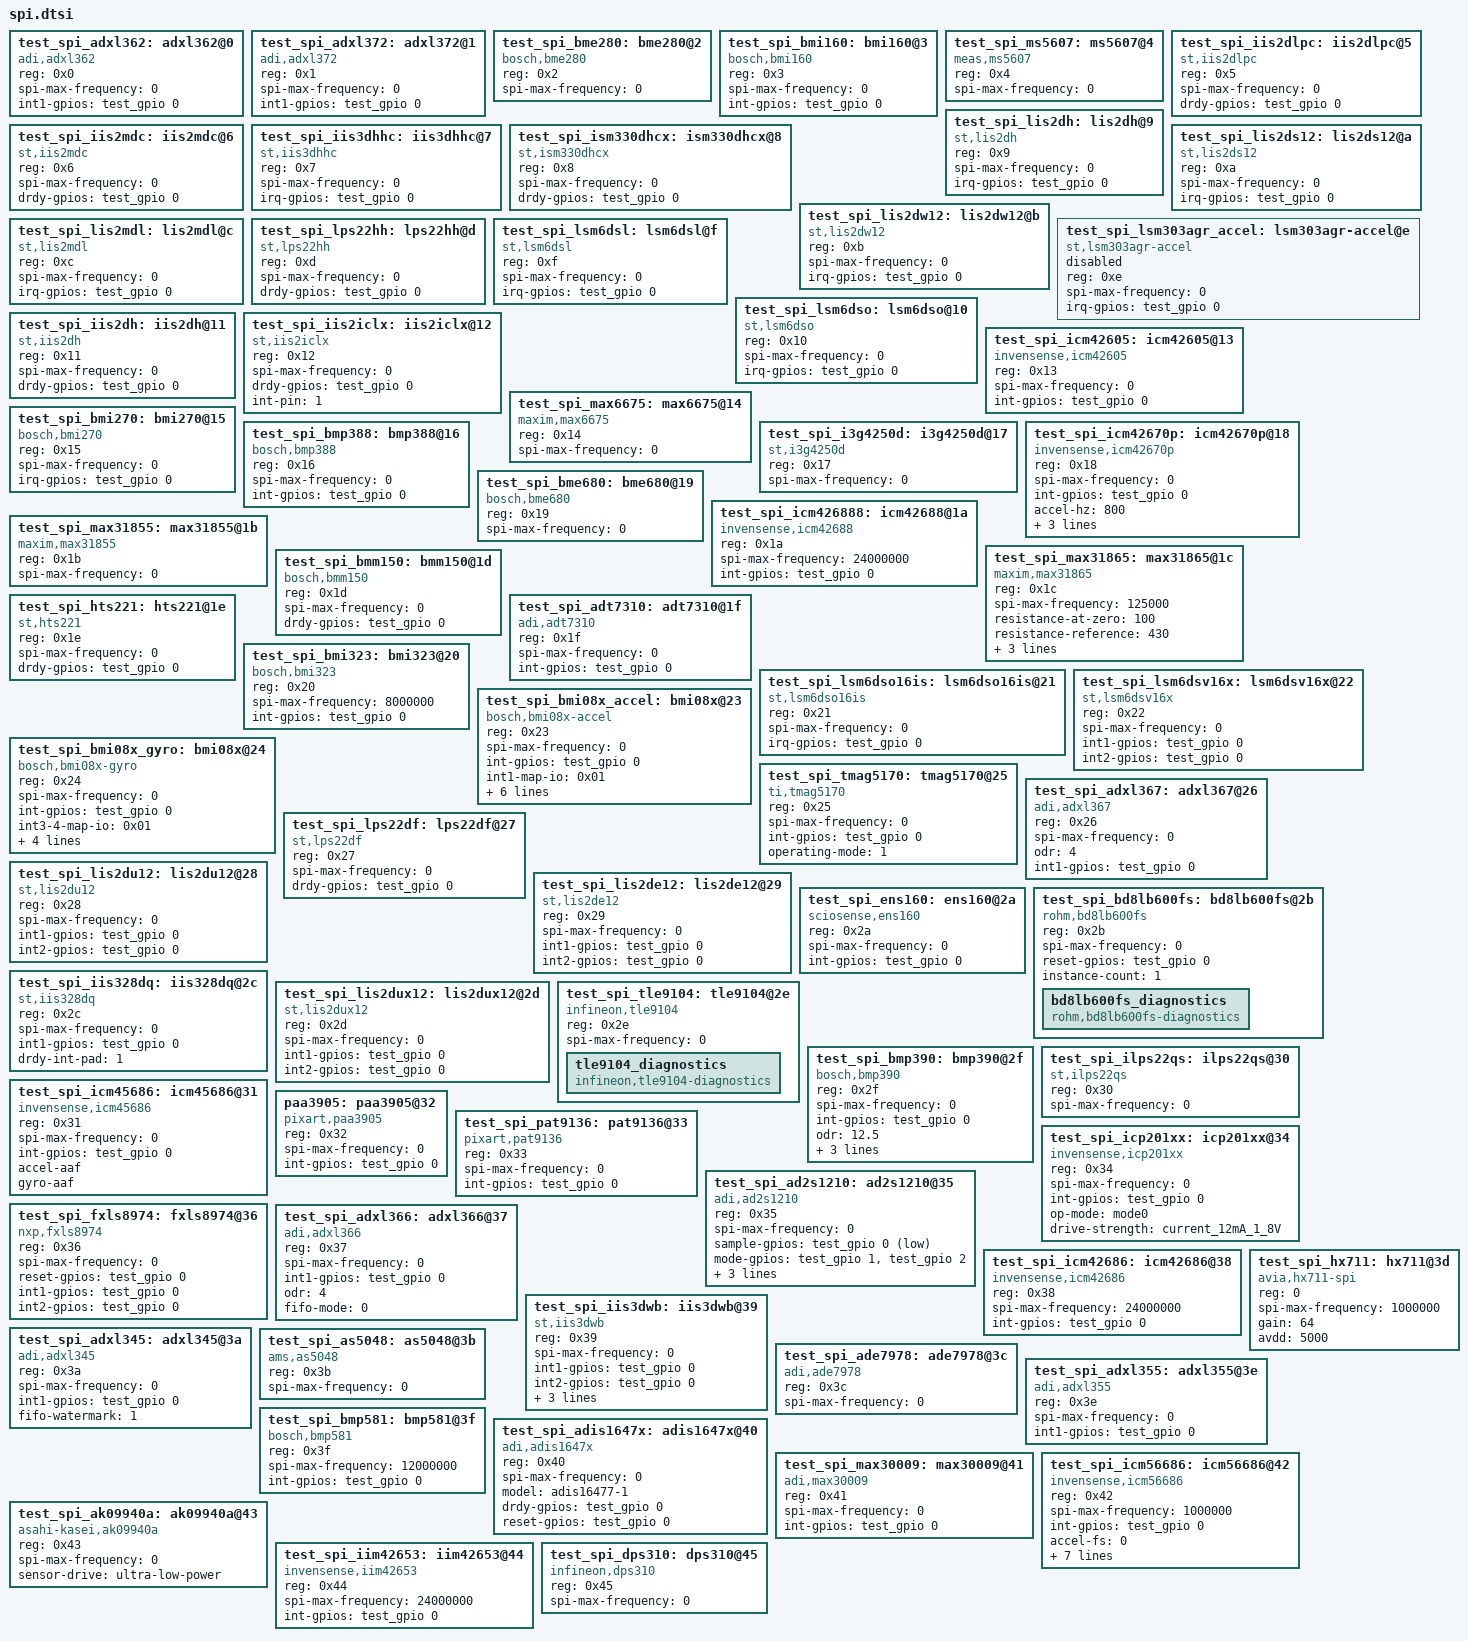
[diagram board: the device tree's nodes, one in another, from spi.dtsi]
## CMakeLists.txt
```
# SPDX-License-Identifier: Apache-2.0

cmake_minimum_required(VERSION 3.28.3)
find_package(Zephyr REQUIRED HINTS $ENV{ZEPHYR_BASE})
project(build_all)

# Exclude main when running the generic test because ztest supplies its own
target_sources_ifndef(CONFIG_GENERIC_SENSOR_TEST app PRIVATE src/main.c)
target_sources_ifdef(CONFIG_GENERIC_SENSOR_TEST app PRIVATE src/generic_test.c)
```

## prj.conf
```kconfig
# zephyr-keep-sorted-start
CONFIG_ADC=y
CONFIG_DAC=y
CONFIG_DHT20_CRC=y
CONFIG_EMUL=y
CONFIG_FUEL_GAUGE=y
CONFIG_GPIO=y
CONFIG_I2C=y
CONFIG_I3C=y
CONFIG_ICM42605_TRIGGER_NONE=y
CONFIG_ICM566XX_TRIGGER_NONE=y
CONFIG_LOG=y
CONFIG_MFD=y
CONFIG_MODBUS=y
CONFIG_MODBUS_RAW_ADU=y
CONFIG_PWM=y
CONFIG_PWM_CAPTURE=y
CONFIG_SENSOR=y
CONFIG_SENSOR_LOG_LEVEL_DBG=y
CONFIG_SERIAL=y
CONFIG_SPI=y
CONFIG_SYS_CLOCK_TICKS_PER_SEC=1000
CONFIG_TEST=y
CONFIG_TEST_USERSPACE=y
CONFIG_VCNL4040_ENABLE_ALS=y
CONFIG_W1=y
# zephyr-keep-sorted-stop
```

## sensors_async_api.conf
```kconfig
CONFIG_SENSOR_ASYNC_API=y
CONFIG_ADXL345_STREAM=y
CONFIG_ADXL362_STREAM=y
CONFIG_ADXL367_STREAM=y
CONFIG_ADXL372_STREAM=y
CONFIG_BMA4XX_STREAM=y
CONFIG_BMM350_STREAM=y
CONFIG_PAA3905_STREAM=y
CONFIG_PAT9136_STREAM=y
CONFIG_RM3100_STREAM=y
CONFIG_IIS3DWB_STREAM=y
CONFIG_LSM6DSV16X_STREAM=y
CONFIG_ICM45686_STREAM=y
CONFIG_ICM4268X_STREAM=y
CONFIG_BMI08X_GYRO_STREAM=y
CONFIG_BMI08X_ACCEL_STREAM=y
CONFIG_MAX30009_STREAM=y
CONFIG_SPA06_STREAM=y
```

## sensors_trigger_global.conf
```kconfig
# zephyr-keep-sorted-start
CONFIG_ADT7310_TRIGGER_GLOBAL_THREAD=y
CONFIG_ADT7420_TRIGGER_GLOBAL_THREAD=y
CONFIG_ADXL355_TRIGGER_GLOBAL_THREAD=y
CONFIG_ADXL362_TRIGGER_GLOBAL_THREAD=y
CONFIG_ADXL367_TRIGGER_GLOBAL_THREAD=y
CONFIG_ADXL372_TRIGGER_GLOBAL_THREAD=y
CONFIG_AMG88XX_TRIGGER_GLOBAL_THREAD=y
CONFIG_APDS9960_TRIGGER_GLOBAL_THREAD=y
CONFIG_BMA280_TRIGGER_GLOBAL_THREAD=y
CONFIG_BMG160_TRIGGER_GLOBAL_THREAD=y
CONFIG_BMI08X_ACCEL_TRIGGER_GLOBAL_THREAD=y
CONFIG_BMI08X_GYRO_TRIGGER_GLOBAL_THREAD=y
CONFIG_BMI160_TRIGGER_GLOBAL_THREAD=y
CONFIG_BMI270_TRIGGER_GLOBAL_THREAD=y
CONFIG_BMM150_TRIGGER_GLOBAL_THREAD=y
CONFIG_BMP388_TRIGGER_GLOBAL_THREAD=y
CONFIG_BQ274XX_TRIGGER_GLOBAL_THREAD=y
CONFIG_CCS811_TRIGGER_GLOBAL_THREAD=y
CONFIG_ENS160_TRIGGER_GLOBAL_THREAD=y
CONFIG_FDC2X1X_TRIGGER_GLOBAL_THREAD=y
CONFIG_FXAS21002_TRIGGER_GLOBAL_THREAD=y
CONFIG_FXLS8974_TRIGGER_GLOBAL_THREAD=y
CONFIG_FXOS8700_TRIGGER_GLOBAL_THREAD=y
CONFIG_GROW_R502A_TRIGGER_GLOBAL_THREAD=y
CONFIG_HMC5883L_TRIGGER_GLOBAL_THREAD=y
CONFIG_HTS221_TRIGGER_GLOBAL_THREAD=y
CONFIG_ICM42605_TRIGGER_GLOBAL_THREAD=y
CONFIG_ICM4268X_TRIGGER_GLOBAL_THREAD=y
CONFIG_ICM42X70_TRIGGER_GLOBAL_THREAD=y
CONFIG_ICM45686_TRIGGER_GLOBAL_THREAD=y
CONFIG_ICP201XX_TRIGGER_GLOBAL_THREAD=y
CONFIG_IIS2DH_TRIGGER_GLOBAL_THREAD=y
CONFIG_IIS2DLPC_TRIGGER_GLOBAL_THREAD=y
CONFIG_IIS2ICLX_TRIGGER_GLOBAL_THREAD=y
CONFIG_IIS2MDC_TRIGGER_GLOBAL_THREAD=y
CONFIG_IIS328DQ_TRIGGER_GLOBAL_THREAD=y
CONFIG_IIS3DHHC_TRIGGER_GLOBAL_THREAD=y
CONFIG_ISL29035_TRIGGER_GLOBAL_THREAD=y
CONFIG_ISM330DHCX_TRIGGER_GLOBAL_THREAD=y
CONFIG_JC42_TRIGGER_GLOBAL_THREAD=y
CONFIG_LIS2DE12_TRIGGER_GLOBAL_THREAD=y
CONFIG_LIS2DH_TRIGGER_GLOBAL_THREAD=y
CONFIG_LIS2DS12_TRIGGER_GLOBAL_THREAD=y
CONFIG_LIS2DU12_TRIGGER_GLOBAL_THREAD=y
CONFIG_LIS2DUX12_TRIGGER_GLOBAL_THREAD=y
CONFIG_LIS2DW12_TRIGGER_GLOBAL_THREAD=y
CONFIG_LIS2MDL_TRIGGER_GLOBAL_THREAD=y
CONFIG_LIS3MDL_TRIGGER_GLOBAL_THREAD=y
CONFIG_LM75_TRIGGER_GLOBAL_THREAD=y
CONFIG_LPS22HH_TRIGGER_GLOBAL_THREAD=y
CONFIG_LPS2XDF_TRIGGER_GLOBAL_THREAD=y
CONFIG_LSM6DSL_TRIGGER_GLOBAL_THREAD=y
CONFIG_LSM6DSO16IS_TRIGGER_GLOBAL_THREAD=y
CONFIG_LSM6DSO_TRIGGER_GLOBAL_THREAD=y
CONFIG_LSM6DSV16X_TRIGGER_GLOBAL_THREAD=y
CONFIG_LTC4286_TRIGGER_GLOBAL_THREAD=y
CONFIG_MAX30009_TRIGGER_GLOBAL_THREAD=y
CONFIG_MAX30210_TRIGGER_GLOBAL_THREAD=y
CONFIG_MPU6050_TRIGGER_GLOBAL_THREAD=y
CONFIG_MPU9250_TRIGGER_GLOBAL_THREAD=y
CONFIG_OPT300X_TRIGGER_GLOBAL_THREAD=y
CONFIG_QMI8658A_TRIGGER_GLOBAL_THREAD=y
CONFIG_SHT3XD_TRIGGER_GLOBAL_THREAD=y
CONFIG_SM351LT_TRIGGER_GLOBAL_THREAD=y
CONFIG_SPA06_TRIGGER_GLOBAL_THREAD=y
CONFIG_STTS22H_TRIGGER_GLOBAL_THREAD=y
CONFIG_STTS751_TRIGGER_GLOBAL_THREAD=y
CONFIG_SX9500_TRIGGER_GLOBAL_THREAD=y
CONFIG_TCN75A_TRIGGER_GLOBAL_THREAD=y
CONFIG_TMAG5170_TRIGGER_GLOBAL_THREAD=y
CONFIG_TMD2620_TRIGGER_GLOBAL_THREAD=y
CONFIG_TMP007_TRIGGER_GLOBAL_THREAD=y
CONFIG_TMP11X_TRIGGER_GLOBAL_THREAD=y
CONFIG_TMP451_TRIGGER_GLOBAL_THREAD=y
CONFIG_TSL2540_TRIGGER_GLOBAL_THREAD=y
CONFIG_TSL2591_TRIGGER_GLOBAL_THREAD=y
CONFIG_VCNL36825T_TRIGGER_GLOBAL_THREAD=y
CONFIG_VCNL4040_TRIGGER_GLOBAL_THREAD=y
CONFIG_WSEN_ISDS_2536030320001_TRIGGER_GLOBAL_THREAD=y
CONFIG_WSEN_ITDS_2533020201601_TRIGGER_GLOBAL_THREAD=y
CONFIG_WSEN_PADS_2511020213301_TRIGGER_GLOBAL_THREAD=y
CONFIG_WSEN_TIDS_2521020222501_TRIGGER_GLOBAL_THREAD=y
# zephyr-keep-sorted-stop
```

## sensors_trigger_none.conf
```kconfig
# zephyr-keep-sorted-start
CONFIG_ADT7310_TRIGGER_NONE=y
CONFIG_ADT7420_TRIGGER_NONE=y
CONFIG_ADXL355_TRIGGER_NONE=y
CONFIG_ADXL362_TRIGGER_NONE=y
CONFIG_ADXL367_TRIGGER_NONE=y
CONFIG_ADXL372_TRIGGER_NONE=y
CONFIG_AMG88XX_TRIGGER_NONE=y
CONFIG_APDS9960_TRIGGER_NONE=y
CONFIG_BMA280_TRIGGER_NONE=y
CONFIG_BMG160_TRIGGER_NONE=y
CONFIG_BMI08X_ACCEL_TRIGGER_NONE=y
CONFIG_BMI08X_GYRO_TRIGGER_NONE=y
CONFIG_BMI160_TRIGGER_NONE=y
CONFIG_BMI270_TRIGGER_NONE=y
CONFIG_BMM150_TRIGGER_NONE=y
CONFIG_BMM350_TRIGGER_NONE=y
CONFIG_BMP388_TRIGGER_NONE=y
CONFIG_BQ274XX_TRIGGER_NONE=y
CONFIG_CCS811_TRIGGER_NONE=y
CONFIG_ENS160_TRIGGER_NONE=y
CONFIG_FDC2X1X_TRIGGER_NONE=y
CONFIG_FXAS21002_TRIGGER_NONE=y
CONFIG_FXLS8974_TRIGGER_NONE=y
CONFIG_FXOS8700_TRIGGER_NONE=y
CONFIG_GROW_R502A_TRIGGER_NONE=y
CONFIG_HMC5883L_TRIGGER_NONE=y
CONFIG_HTS221_TRIGGER_NONE=y
CONFIG_ICM42605_TRIGGER_NONE=y
CONFIG_ICM4268X_TRIGGER_NONE=y
CONFIG_ICM42X70_TRIGGER_NONE=y
CONFIG_ICM45686_TRIGGER_NONE=y
CONFIG_ICP201XX_TRIGGER_NONE=y
CONFIG_IIS2DH_TRIGGER_NONE=y
CONFIG_IIS2DLPC_TRIGGER_NONE=y
CONFIG_IIS2ICLX_TRIGGER_NONE=y
CONFIG_IIS2MDC_TRIGGER_NONE=y
CONFIG_IIS328DQ_TRIGGER_NONE=y
CONFIG_IIS3DHHC_TRIGGER_NONE=y
CONFIG_ISL29035_TRIGGER_NONE=y
CONFIG_ISM330DHCX_TRIGGER_NONE=y
CONFIG_JC42_TRIGGER_NONE=y
CONFIG_LIS2DE12_TRIGGER_NONE=y
CONFIG_LIS2DH_TRIGGER_NONE=y
CONFIG_LIS2DS12_TRIGGER_NONE=y
CONFIG_LIS2DU12_TRIGGER_NONE=y
CONFIG_LIS2DUX12_TRIGGER_NONE=y
CONFIG_LIS2DW12_TRIGGER_NONE=y
CONFIG_LIS2MDL_TRIGGER_NONE=y
CONFIG_LIS3MDL_TRIGGER_NONE=y
CONFIG_LM75_TRIGGER_NONE=y
CONFIG_LPS22HH_TRIGGER_NONE=y
CONFIG_LPS2XDF_TRIGGER_NONE=y
CONFIG_LSM6DSL_TRIGGER_NONE=y
CONFIG_LSM6DSO16IS_TRIGGER_NONE=y
CONFIG_LSM6DSO_TRIGGER_NONE=y
CONFIG_LSM6DSV16X_TRIGGER_NONE=y
CONFIG_LTC4286_TRIGGER_NONE=y
CONFIG_MAX30009_TRIGGER_NONE=y
CONFIG_MAX30210_TRIGGER_NONE=y
CONFIG_MC3419_TRIGGER_NONE=y
CONFIG_MPU6050_TRIGGER_NONE=y
CONFIG_MPU9250_TRIGGER_NONE=y
CONFIG_OPT300X_TRIGGER_NONE=y
CONFIG_QMI8658A_TRIGGER_NONE=y
CONFIG_SHT3XD_TRIGGER_NONE=y
CONFIG_SM351LT_TRIGGER_NONE=y
CONFIG_SPA06_TRIGGER_NONE=y
CONFIG_STTS22H_TRIGGER_NONE=y
CONFIG_STTS751_TRIGGER_NONE=y
CONFIG_SX9500_TRIGGER_NONE=y
CONFIG_TCN75A_TRIGGER_NONE=y
CONFIG_TMAG5170_TRIGGER_NONE=y
CONFIG_TMD2620_TRIGGER_NONE=y
CONFIG_TMP007_TRIGGER_NONE=y
CONFIG_TMP11X_TRIGGER_NONE=y
CONFIG_TMP451_TRIGGER_NONE=y
CONFIG_TSL2540_TRIGGER_NONE=y
CONFIG_TSL2591_TRIGGER_NONE=y
CONFIG_VCNL36825T_TRIGGER_NONE=y
CONFIG_VCNL4040_TRIGGER_NONE=y
CONFIG_WSEN_ISDS_2536030320001_TRIGGER_NONE=y
CONFIG_WSEN_ITDS_2533020201601_TRIGGER_NONE=y
CONFIG_WSEN_PADS_2511020213301_TRIGGER_NONE=y
CONFIG_WSEN_TIDS_2521020222501_TRIGGER_NONE=y
# zephyr-keep-sorted-stop
```

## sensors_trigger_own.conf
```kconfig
# zephyr-keep-sorted-start
CONFIG_ADT7310_TRIGGER_OWN_THREAD=y
CONFIG_ADT7420_TRIGGER_OWN_THREAD=y
CONFIG_ADXL355_TRIGGER_OWN_THREAD=y
CONFIG_ADXL362_TRIGGER_OWN_THREAD=y
CONFIG_ADXL367_TRIGGER_OWN_THREAD=y
CONFIG_ADXL372_TRIGGER_OWN_THREAD=y
CONFIG_AMG88XX_TRIGGER_OWN_THREAD=y
CONFIG_BMA280_TRIGGER_OWN_THREAD=y
CONFIG_BMG160_TRIGGER_OWN_THREAD=y
CONFIG_BMI08X_ACCEL_TRIGGER_OWN_THREAD=y
CONFIG_BMI08X_GYRO_TRIGGER_OWN_THREAD=y
CONFIG_BMI160_TRIGGER_OWN_THREAD=y
CONFIG_BMI270_TRIGGER_OWN_THREAD=y
CONFIG_BMM150_TRIGGER_OWN_THREAD=y
CONFIG_BMM350_TRIGGER_OWN_THREAD=y
CONFIG_BMP388_TRIGGER_OWN_THREAD=y
CONFIG_BQ274XX_TRIGGER_OWN_THREAD=y
CONFIG_CCS811_TRIGGER_OWN_THREAD=y
CONFIG_ENS160_TRIGGER_OWN_THREAD=y
CONFIG_FDC2X1X_TRIGGER_OWN_THREAD=y
CONFIG_FXAS21002_TRIGGER_OWN_THREAD=y
CONFIG_FXLS8974_TRIGGER_OWN_THREAD=y
CONFIG_FXOS8700_TRIGGER_OWN_THREAD=y
CONFIG_GROW_R502A_TRIGGER_OWN_THREAD=y
CONFIG_HMC5883L_TRIGGER_OWN_THREAD=y
CONFIG_HTS221_TRIGGER_OWN_THREAD=y
CONFIG_ICM4268X_TRIGGER_OWN_THREAD=y
CONFIG_ICM42X70_TRIGGER_OWN_THREAD=y
CONFIG_ICM45686_TRIGGER_OWN_THREAD=y
CONFIG_ICP201XX_TRIGGER_OWN_THREAD=y
CONFIG_IIS2DH_TRIGGER_OWN_THREAD=y
CONFIG_IIS2DLPC_TRIGGER_OWN_THREAD=y
CONFIG_IIS2ICLX_TRIGGER_OWN_THREAD=y
CONFIG_IIS2MDC_TRIGGER_OWN_THREAD=y
CONFIG_IIS328DQ_TRIGGER_OWN_THREAD=y
CONFIG_IIS3DHHC_TRIGGER_OWN_THREAD=y
CONFIG_ISL29035_TRIGGER_OWN_THREAD=y
CONFIG_ISM330DHCX_TRIGGER_OWN_THREAD=y
CONFIG_JC42_TRIGGER_OWN_THREAD=y
CONFIG_LIS2DE12_TRIGGER_OWN_THREAD=y
CONFIG_LIS2DH_TRIGGER_OWN_THREAD=y
CONFIG_LIS2DS12_TRIGGER_OWN_THREAD=y
CONFIG_LIS2DU12_TRIGGER_OWN_THREAD=y
CONFIG_LIS2DUX12_TRIGGER_OWN_THREAD=y
CONFIG_LIS2DW12_TRIGGER_OWN_THREAD=y
CONFIG_LIS2MDL_TRIGGER_OWN_THREAD=y
CONFIG_LIS3MDL_TRIGGER_OWN_THREAD=y
CONFIG_LPS22HH_TRIGGER_OWN_THREAD=y
CONFIG_LPS2XDF_TRIGGER_OWN_THREAD=y
CONFIG_LSM6DSL_TRIGGER_OWN_THREAD=y
CONFIG_LSM6DSO16IS_TRIGGER_OWN_THREAD=y
CONFIG_LSM6DSO_TRIGGER_OWN_THREAD=y
CONFIG_LSM6DSV16X_TRIGGER_OWN_THREAD=y
CONFIG_LTC4286_TRIGGER_OWN_THREAD=y
CONFIG_MAX30009_TRIGGER_OWN_THREAD=y
CONFIG_MAX30210_TRIGGER_OWN_THREAD=y
CONFIG_MC3419_TRIGGER_OWN_THREAD=y
CONFIG_MPU6050_TRIGGER_OWN_THREAD=y
CONFIG_MPU9250_TRIGGER_OWN_THREAD=y
CONFIG_OPT300X_TRIGGER_OWN_THREAD=y
CONFIG_QMI8658A_TRIGGER_OWN_THREAD=y
CONFIG_SHT3XD_TRIGGER_OWN_THREAD=y
CONFIG_SM351LT_TRIGGER_OWN_THREAD=y
CONFIG_SPA06_TRIGGER_OWN_THREAD=y
CONFIG_STTS22H_TRIGGER_OWN_THREAD=y
CONFIG_STTS751_TRIGGER_OWN_THREAD=y
CONFIG_SX9500_TRIGGER_OWN_THREAD=y
CONFIG_TCN75A_TRIGGER_OWN_THREAD=y
CONFIG_TMAG5170_TRIGGER_OWN_THREAD=y
CONFIG_TMP007_TRIGGER_OWN_THREAD=y
CONFIG_TMP11X_TRIGGER_OWN_THREAD=y
CONFIG_TMP451_TRIGGER_OWN_THREAD=y
CONFIG_TSL2540_TRIGGER_OWN_THREAD=y
CONFIG_TSL2591_TRIGGER_OWN_THREAD=y
CONFIG_VCNL36825T_TRIGGER_OWN_THREAD=y
CONFIG_VCNL4040_TRIGGER_OWN_THREAD=y
CONFIG_WSEN_ISDS_2536030320001_TRIGGER_OWN_THREAD=y
CONFIG_WSEN_ITDS_2533020201601_TRIGGER_OWN_THREAD=y
CONFIG_WSEN_PADS_2511020213301_TRIGGER_OWN_THREAD=y
CONFIG_WSEN_TIDS_2521020222501_TRIGGER_OWN_THREAD=y
# zephyr-keep-sorted-stop
```

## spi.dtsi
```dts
/*
 * Copyright (c) 2020, Linaro Ltd.
 *
 * SPDX-License-Identifier: Apache-2.0
 *
 * Application overlay for spi devices
 */

#include <zephyr/dt-bindings/gpio/gpio.h>
#include <zephyr/dt-bindings/sensor/iis3dwb.h>

/****************************************
 * PLEASE KEEP REG ADDRESSES SEQUENTIAL *
 **************************************
 */

test_spi_adxl362: adxl362@0 {
	compatible = "adi,adxl362";
	reg = <0x0>;
	spi-max-frequency = <0>;
	int1-gpios = <&test_gpio 0 0>;
};

test_spi_adxl372: adxl372@1 {
	compatible = "adi,adxl372";
	reg = <0x1>;
	spi-max-frequency = <0>;
	int1-gpios = <&test_gpio 0 0>;
};

test_spi_bme280: bme280@2 {
	compatible = "bosch,bme280";
	reg = <0x2>;
	spi-max-frequency = <0>;
};

test_spi_bmi160: bmi160@3 {
	compatible = "bosch,bmi160";
	reg = <0x3>;
	spi-max-frequency = <0>;
	int-gpios = <&test_gpio 0 0>;
};

test_spi_ms5607: ms5607@4 {
	compatible = "meas,ms5607";
	reg = <0x4>;
	spi-max-frequency = <0>;
};

test_spi_iis2dlpc: iis2dlpc@5 {
	compatible = "st,iis2dlpc";
	reg = <0x5>;
	spi-max-frequency = <0>;
	drdy-gpios = <&test_gpio 0 0>;
};

test_spi_iis2mdc: iis2mdc@6 {
	compatible = "st,iis2mdc";
	reg = <0x6>;
	spi-max-frequency = <0>;
	drdy-gpios = <&test_gpio 0 0>;
};

test_spi_iis3dhhc: iis3dhhc@7 {
	compatible = "st,iis3dhhc";
	reg = <0x7>;
	spi-max-frequency = <0>;
	irq-gpios = <&test_gpio 0 0>;
};

test_spi_ism330dhcx: ism330dhcx@8 {
	compatible = "st,ism330dhcx";
	reg = <0x8>;
	spi-max-frequency = <0>;
	drdy-gpios = <&test_gpio 0 0>;
};

test_spi_lis2dh: lis2dh@9 {
	compatible = "st,lis2dh";
	reg = <0x9>;
	spi-max-frequency = <0>;
	irq-gpios = <&test_gpio 0 0>;
	/* disconnect-sdo-sa0-pull-up; */
};

test_spi_lis2ds12: lis2ds12@a {
	compatible = "st,lis2ds12";
	reg = <0xa>;
	spi-max-frequency = <0>;
	irq-gpios = <&test_gpio 0 0>;
};

test_spi_lis2dw12: lis2dw12@b {
	compatible = "st,lis2dw12";
	reg = <0xb>;
	spi-max-frequency = <0>;
	irq-gpios = <&test_gpio 0 0>;
};

test_spi_lis2mdl: lis2mdl@c {
	compatible = "st,lis2mdl";
	reg = <0xc>;
	spi-max-frequency = <0>;
	irq-gpios = <&test_gpio 0 0>;
};

test_spi_lps22hh: lps22hh@d {
	compatible = "st,lps22hh";
	reg = <0xd>;
	spi-max-frequency = <0>;
	drdy-gpios = <&test_gpio 0 0>;
};

test_spi_lsm303agr_accel: lsm303agr-accel@e {
	compatible = "st,lsm303agr-accel";
	reg = <0xe>;
	spi-max-frequency = <0>;
	irq-gpios = <&test_gpio 0 0>;
	/* disconnect-sdo-sa0-pull-up; */
	status = "disabled";
};

test_spi_lsm6dsl: lsm6dsl@f {
	compatible = "st,lsm6dsl";
	reg = <0xf>;
	spi-max-frequency = <0>;
	irq-gpios = <&test_gpio 0 0>;
};

test_spi_lsm6dso: lsm6dso@10 {
	compatible = "st,lsm6dso";
	reg = <0x10>;
	spi-max-frequency = <0>;
	irq-gpios = <&test_gpio 0 0>;
};

test_spi_iis2dh: iis2dh@11 {
	compatible = "st,iis2dh";
	reg = <0x11>;
	spi-max-frequency = <0>;
	drdy-gpios = <&test_gpio 0 0>;
};

test_spi_iis2iclx: iis2iclx@12 {
	compatible = "st,iis2iclx";
	reg = <0x12>;
	spi-max-frequency = <0>;
	drdy-gpios = <&test_gpio 0 0>;
	int-pin = <1>;
};

test_spi_icm42605: icm42605@13 {
	compatible = "invensense,icm42605";
	reg = <0x13>;
	spi-max-frequency = <0>;
	int-gpios = <&test_gpio 0 0>;
};

test_spi_max6675: max6675@14 {
	compatible = "maxim,max6675";
	reg = <0x14>;
	spi-max-frequency = <0>;
};

test_spi_bmi270: bmi270@15 {
	compatible = "bosch,bmi270";
	reg = <0x15>;
	spi-max-frequency = <0>;
	irq-gpios = <&test_gpio 0 0>;
};

test_spi_bmp388: bmp388@16 {
	compatible = "bosch,bmp388";
	reg = <0x16>;
	spi-max-frequency = <0>;
	int-gpios = <&test_gpio 0 0>;
};

test_spi_i3g4250d: i3g4250d@17 {
	compatible = "st,i3g4250d";
	reg = <0x17>;
	spi-max-frequency = <0>;
};

test_spi_icm42670p: icm42670p@18 {
	compatible = "invensense,icm42670p";
	reg = <0x18>;
	spi-max-frequency = <0>;
	int-gpios = <&test_gpio 0 0>;
	accel-hz = <800>;
	accel-fs = <16>;
	gyro-hz = <800>;
	gyro-fs = <2000>;
};

test_spi_bme680: bme680@19 {
	compatible = "bosch,bme680";
	reg = <0x19>;
	spi-max-frequency = <0>;
};

test_spi_icm426888: icm42688@1a {
	compatible = "invensense,icm42688", "invensense,icm4268x";
	reg = <0x1a>;
	spi-max-frequency = <24000000>;
	int-gpios = <&test_gpio 0 0>;
};

test_spi_max31855: max31855@1b {
	compatible = "maxim,max31855";
	reg = <0x1b>;
	spi-max-frequency = <0>;
};

test_spi_max31865: max31865@1c {
	compatible = "maxim,max31865";
	reg = <0x1c>;
	spi-max-frequency = <125000>;
	resistance-at-zero = <100>;
	resistance-reference = <430>;
	low-threshold = <6579>;
	high-threshold = <32767>;
	filter-50hz;
};

test_spi_bmm150: bmm150@1d {
	compatible = "bosch,bmm150";
	reg = <0x1d>;
	spi-max-frequency = <0>;
	drdy-gpios = <&test_gpio 0 0>;
};

test_spi_hts221: hts221@1e {
	compatible = "st,hts221";
	reg = <0x1e>;
	spi-max-frequency = <0>;
	drdy-gpios = <&test_gpio 0 0>;
};

test_spi_adt7310: adt7310@1f {
	compatible = "adi,adt7310";
	reg = <0x1f>;
	spi-max-frequency = <0>;
	int-gpios = <&test_gpio 0 0>;
};

test_spi_bmi323: bmi323@20 {
	compatible = "bosch,bmi323";
	reg = <0x20>;
	spi-max-frequency = <8000000>;
	int-gpios = <&test_gpio 0 0>;
};

test_spi_lsm6dso16is: lsm6dso16is@21 {
	compatible = "st,lsm6dso16is";
	reg = <0x21>;
	spi-max-frequency = <0>;
	irq-gpios = <&test_gpio 0 0>;
};

test_spi_lsm6dsv16x: lsm6dsv16x@22 {
	compatible = "st,lsm6dsv16x";
	reg = <0x22>;
	spi-max-frequency = <0>;
	int1-gpios = <&test_gpio 0 0>;
	int2-gpios = <&test_gpio 0 0>;
};

test_spi_bmi08x_accel: bmi08x@23 {
	compatible = "bosch,bmi08x-accel";
	reg = <0x23>;
	spi-max-frequency = <0>;
	int-gpios = <&test_gpio 0 0>;
	int1-map-io = <0x01>;
	int2-map-io = <0x00>;
	int1-conf-io = <0x0a>;
	int2-conf-io = <0x17>;
	accel-hz = "800";
	accel-fs = <4>;
	fifo-watermark = <1>;
};

test_spi_bmi08x_gyro: bmi08x@24 {
	compatible = "bosch,bmi08x-gyro";
	reg = <0x24>;
	spi-max-frequency = <0>;
	int-gpios = <&test_gpio 0 0>;
	int3-4-map-io = <0x01>;
	int3-4-conf-io = <0x01>;
	gyro-hz = "1000_116";
	gyro-fs = <1000>;
	fifo-watermark = <1>;
};

test_spi_tmag5170: tmag5170@25 {
	compatible = "ti,tmag5170";
	reg = <0x25>;
	spi-max-frequency = <0>;
	int-gpios = <&test_gpio 0 0>;
	operating-mode = <1>;
};

test_spi_adxl367: adxl367@26 {
	compatible = "adi,adxl367";
	reg = <0x26>;
	spi-max-frequency = <0>;
	odr = <4>;
	int1-gpios = <&test_gpio 0 0>;
};

test_spi_lps22df: lps22df@27 {
	compatible = "st,lps22df";
	reg = <0x27>;
	spi-max-frequency = <0>;
	drdy-gpios = <&test_gpio 0 0>;
	status = "okay";
};

test_spi_lis2du12: lis2du12@28 {
	compatible = "st,lis2du12";
	reg = <0x28>;
	spi-max-frequency = <0>;
	int1-gpios = <&test_gpio 0 0>;
	int2-gpios = <&test_gpio 0 0>;
	status = "okay";
};

test_spi_lis2de12: lis2de12@29 {
	compatible = "st,lis2de12";
	reg = <0x29>;
	spi-max-frequency = <0>;
	int1-gpios = <&test_gpio 0 0>;
	int2-gpios = <&test_gpio 0 0>;
	status = "okay";
};

test_spi_ens160: ens160@2a {
	compatible = "sciosense,ens160";
	reg = <0x2a>;
	spi-max-frequency = <0>;
	int-gpios = <&test_gpio 0 0>;
};

test_spi_bd8lb600fs: bd8lb600fs@2b {
	compatible = "rohm,bd8lb600fs";
	reg = <0x2b>;
	spi-max-frequency = <0>;
	reset-gpios = <&test_gpio 0 0>;
	instance-count = <1>;
	status = "okay";

	bd8lb600fs_diagnostics: bd8lb600fs_diagnostics {
		compatible = "rohm,bd8lb600fs-diagnostics";
		#sensor-cells = <0>;
		status = "okay";
	};
};

test_spi_iis328dq: iis328dq@2c {
	compatible = "st,iis328dq";
	reg = <0x2c>;
	spi-max-frequency = <0>;
	int1-gpios = <&test_gpio 0 0>;
	drdy-int-pad = <1>;
	status = "okay";
};

test_spi_lis2dux12: lis2dux12@2d {
	compatible = "st,lis2dux12";
	reg = <0x2d>;
	spi-max-frequency = <0>;
	int1-gpios = <&test_gpio 0 0>;
	int2-gpios = <&test_gpio 0 0>;
	status = "okay";
};

test_spi_tle9104: tle9104@2e {
	compatible = "infineon,tle9104";
	reg = <0x2e>;
	spi-max-frequency = <0>;
	status = "okay";

	tle9104_diagnostics: tle9104_diagnostics {
		compatible = "infineon,tle9104-diagnostics";
		#sensor-cells = <0>;
		status = "okay";
	};
};

test_spi_bmp390: bmp390@2f {
	compatible = "bosch,bmp390";
	reg = <0x2f>;
	spi-max-frequency = <0>;
	int-gpios = <&test_gpio 0 0>;
	odr = "12.5";
	osr-press = <8>;
	osr-temp = <1>;
	iir-filter = <3>;
};

test_spi_ilps22qs: ilps22qs@30 {
	compatible = "st,ilps22qs";
	reg = <0x30>;
	spi-max-frequency = <0>;
	status = "okay";
};

test_spi_icm45686: icm45686@31 {
	compatible = "invensense,icm45686";
	reg = <0x31>;
	spi-max-frequency = <0>;
	int-gpios = <&test_gpio 0 0>;
	accel-aaf;
	gyro-aaf;
};

paa3905: paa3905@32 {
	compatible = "pixart,paa3905";
	reg = <0x32>;
	spi-max-frequency = <0>;
	int-gpios = <&test_gpio 0 0>;
};

test_spi_pat9136: pat9136@33 {
	compatible = "pixart,pat9136";
	reg = <0x33>;
	spi-max-frequency = <0>;
	int-gpios = <&test_gpio 0 0>;
};

test_spi_icp201xx: icp201xx@34 {
	compatible = "invensense,icp201xx";
	reg = <0x34>;
	spi-max-frequency = <0>;
	int-gpios = <&test_gpio 0 0>;
	op-mode = "mode0";
	drive-strength = "current_12mA_1_8V";
};

test_spi_ad2s1210: ad2s1210@35 {
	compatible = "adi,ad2s1210";
	reg = <0x35>;
	spi-max-frequency = <0>;
	sample-gpios = <&test_gpio 0 GPIO_ACTIVE_LOW>;
	mode-gpios = <&test_gpio 1 GPIO_ACTIVE_HIGH>, <&test_gpio 2 GPIO_ACTIVE_HIGH>;
	resolution-gpios = <&test_gpio 3 GPIO_ACTIVE_HIGH>, <&test_gpio 4 GPIO_ACTIVE_HIGH>;
	reset-gpios = <&test_gpio 7 GPIO_ACTIVE_LOW>;
	clock-frequency = <8192000>;
};

test_spi_fxls8974: fxls8974@36 {
	compatible = "nxp,fxls8974";
	reg = <0x36>;
	spi-max-frequency = <0>;
	reset-gpios = <&test_gpio 0 0>;
	int1-gpios = <&test_gpio 0 0>;
	int2-gpios = <&test_gpio 0 0>;
};

test_spi_adxl366: adxl366@37 {
	compatible = "adi,adxl366";
	reg = <0x37>;
	spi-max-frequency = <0>;
	int1-gpios = <&test_gpio 0 0>;
	odr = <4>;
	fifo-mode = <0>;
};

test_spi_icm42686: icm42686@38 {
	compatible = "invensense,icm42686", "invensense,icm4268x";
	reg = <0x38>;
	spi-max-frequency = <24000000>;
	int-gpios = <&test_gpio 0 0>;
};

test_spi_iis3dwb: iis3dwb@39 {
	compatible = "st,iis3dwb";
	reg = <0x39>;
	spi-max-frequency = <0>;
	int1-gpios = <&test_gpio 0 0>;
	int2-gpios = <&test_gpio 0 0>;
	range = <IIS3DWB_DT_FS_16G>;
	odr = <IIS3DWB_DT_ODR_26k7Hz>;
	filter = <IIS3DWB_DT_HP_ODR_DIV_800>;
};

test_spi_adxl345: adxl345@3a {
	compatible = "adi,adxl345";
	reg = <0x3a>;
	spi-max-frequency = <0>;
	int1-gpios = <&test_gpio 0 0>;
	fifo-watermark = <1>;
};

test_spi_as5048: as5048@3b {
	compatible = "ams,as5048";
	reg = <0x3b>;
	spi-max-frequency = <0>;
};

test_spi_ade7978: ade7978@3c {
	compatible = "adi,ade7978";
	reg = <0x3c>;
	spi-max-frequency = <0>;
};

test_spi_hx711: hx711@3d {
	compatible = "avia,hx711-spi";
	reg = <0>;
	spi-max-frequency = <1000000>;
	gain = <64>;
	avdd = <5000>;
};

test_spi_adxl355: adxl355@3e {
	compatible = "adi,adxl355";
	reg = <0x3e>;
	spi-max-frequency = <0>;
	int1-gpios = <&test_gpio 0 0>;
};

test_spi_bmp581: bmp581@3f {
	compatible = "bosch,bmp581";
	reg = <0x3f>;
	spi-max-frequency = <12000000>;
	int-gpios = <&test_gpio 0 0>;
};

test_spi_adis1647x: adis1647x@40 {
	compatible = "adi,adis1647x";
	reg = <0x40>;
	spi-max-frequency = <0>;
	model = "adis16477-1";
	drdy-gpios = <&test_gpio 0 0>;
	reset-gpios = <&test_gpio 0 0>;
};

test_spi_max30009: max30009@41 {
	compatible = "adi,max30009";
	reg = <0x41>;
	spi-max-frequency = <0>;
	int-gpios = <&test_gpio 0 0>;
};

test_spi_icm56686: icm56686@42 {
	compatible = "invensense,icm56686";
	reg = <0x42>;
	spi-max-frequency = <1000000>;
	int-gpios = <&test_gpio 0 GPIO_ACTIVE_HIGH>;

	accel-fs = <0>;
	accel-odr = <13>;
	accel-lpf = <1>;
	accel-pwr-mode = <2>;

	gyro-fs = <0>;
	gyro-odr = <13>;
	gyro-lpf = <1>;
	gyro-pwr-mode = <2>;
};

test_spi_ak09940a: ak09940a@43 {
	compatible = "asahi-kasei,ak09940a";
	reg = <0x43>;
	spi-max-frequency = <0>;
	sensor-drive = "ultra-low-power";
};

test_spi_iim42653: iim42653@44 {
	compatible = "invensense,iim42653", "invensense,icm4268x";
	reg = <0x44>;
	spi-max-frequency = <24000000>;
	int-gpios = <&test_gpio 0 0>;
};

test_spi_dps310: dps310@45 {
	compatible = "infineon,dps310";
	reg = <0x45>;
	spi-max-frequency = <0>;
};
```

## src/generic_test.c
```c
/*
 * Copyright (c) 2023 Google LLC
 * SPDX-License-Identifier: Apache-2.0
 */

#include <zephyr/device.h>
#include <zephyr/drivers/emul_sensor.h>
#include <zephyr/drivers/emul.h>
#include <zephyr/ztest.h>
#include <zephyr/drivers/sensor.h>
#include <zephyr/drivers/sensor_data_types.h>
#include <zephyr/rtio/rtio.h>
#include <zephyr/sys/bitarray.h>

#include <zephyr/logging/log.h>
LOG_MODULE_REGISTER(generic_test);

/**
 * A union of all sensor data types.
 */
union sensor_data_union {
	struct sensor_three_axis_data three_axis;
	struct sensor_occurrence_data occurrence;
	struct sensor_q31_data q31;
	struct sensor_byte_data byte;
	struct sensor_uint64_data uint64;
};

/*
 * Set up an RTIO context that can be shared for all sensors
 */

static struct sensor_chan_spec iodev_all_channels[SENSOR_CHAN_ALL];
static struct sensor_read_config iodev_read_config = {
	.channels = iodev_all_channels,
	.max = SENSOR_CHAN_ALL,
};
RTIO_IODEV_DEFINE(iodev_read, &__sensor_iodev_api, &iodev_read_config);

/* Create the RTIO context to service the reading */
RTIO_DEFINE_WITH_MEMPOOL(sensor_read_rtio_ctx, 1, 1, 4, 64, 4);

/**
 * @brief Prepare the RTIO context for next test
 */
static void before(void *args)
{
	ARG_UNUSED(args);

	/* Clear the array of requested channels */
	memset(iodev_all_channels, 0, sizeof(iodev_all_channels));

	/* Reset the channel count */
	iodev_read_config.count = 0;

	/* Remove previous sensor pointer */
	iodev_read_config.sensor = NULL;

	/* Wipe the mempool by marking every block free */
	zassert_ok(sys_bitarray_clear_region(sensor_read_rtio_ctx.block_pool->bitmap,
					     sensor_read_rtio_ctx.block_pool->info.num_blocks,
					     0));

	/* Flush the SQ and CQ */
	rtio_sqe_drop_all(&sensor_read_rtio_ctx);
	while (rtio_cqe_consume(&sensor_read_rtio_ctx)) {
		;
	}
}

/**
 * @brief Helper function the carries out the generic sensor test for a given sensor device.
 *        Verifies that the device has a suitable emulator that implements the backend API and
 *        skips the test gracefully if not.
 */
static void run_generic_test(const struct device *dev)
{
	zassert_not_null(dev, "Cannot get device pointer. Is this driver properly instantiated?");

	const struct emul *emul = emul_get_binding(dev->name);

	/* Skip this sensor if there is no emulator loaded. */
	if (!emul) {
		ztest_test_skip();
	}

	/* Also skip if this emulator does not implement the backend API. */
	if (!emul_sensor_backend_is_supported(emul)) {
		ztest_test_skip();
	}

	/*
	 * Begin the actual test sequence
	 */

	static struct {
		bool supported;
		bool received;
		q31_t expected_values[CONFIG_GENERIC_SENSOR_TEST_NUM_EXPECTED_VALS];
		q31_t epsilon;
		int8_t expected_value_shift;
	} channel_table[SENSOR_CHAN_ALL];

	memset(channel_table, 0, sizeof(channel_table));

	/* Discover supported channels on this device and fill out our sensor read request */
	for (enum sensor_channel ch = 0; ch < ARRAY_SIZE(channel_table); ch++) {
		if (SENSOR_CHANNEL_3_AXIS(ch)) {
			continue;
		}

		q31_t lower, upper;
		int8_t shift;
		struct sensor_chan_spec ch_spec = {.chan_type = ch, .chan_idx = 0};

		if (emul_sensor_backend_get_sample_range(emul, ch_spec, &lower, &upper,
							 &channel_table[ch].epsilon, &shift) == 0) {
			/* This channel is supported */
			channel_table[ch].supported = true;

			LOG_INF("CH %d: lower=%d, upper=%d, eps=%d, shift=%d", ch, lower, upper,
				channel_table[ch].epsilon, shift);

			/* Add to the list of channels to read */
			iodev_all_channels[iodev_read_config.count++].chan_type = ch;

			/* Generate a set of CONFIG_GENERIC_SENSOR_TEST_NUM_EXPECTED_VALS test
			 * values.
			 */

			channel_table[ch].expected_value_shift = shift;
			for (size_t i = 0; i < CONFIG_GENERIC_SENSOR_TEST_NUM_EXPECTED_VALS; i++) {
				channel_table[ch].expected_values[i] =
					lower +
					(i * ((int64_t)upper - lower) /
					 (CONFIG_GENERIC_SENSOR_TEST_NUM_EXPECTED_VALS - 1));
				LOG_INF("CH %d: Expected value %d/%d: %d", ch, i + 1,
					CONFIG_GENERIC_SENSOR_TEST_NUM_EXPECTED_VALS,
					channel_table[ch].expected_values[i]);
			}
		}
	}
	iodev_read_config.sensor = dev;

	/* Do a read of all channels for quantity CONFIG_GENERIC_SENSOR_TEST_NUM_EXPECTED_VALS
	 * iterations.
	 */

	for (size_t iteration = 0; iteration < CONFIG_GENERIC_SENSOR_TEST_NUM_EXPECTED_VALS;
	     iteration++) {
		int rv;

		/* Reset received flag */
		for (size_t i = 0; i < ARRAY_SIZE(channel_table); i++) {
			channel_table[i].received = false;
		}

		/* Set this iteration's expected values in emul for every supported channel */
		for (size_t i = 0; i < iodev_read_config.count; i++) {
			struct sensor_chan_spec ch_spec = iodev_all_channels[i];

			rv = emul_sensor_backend_set_channel(
				emul, ch_spec,
				&channel_table[ch_spec.chan_type].expected_values[iteration],
				channel_table[ch_spec.chan_type].expected_value_shift);
			zassert_ok(rv,
				   "Cannot set value 0x%08x on channel (type: %d, index: %d) "
				   "(error %d, iteration %d/%d)",
				   channel_table[i].expected_values[iteration], ch_spec.chan_type,
				   ch_spec.chan_idx, rv, iteration + 1,
				   CONFIG_GENERIC_SENSOR_TEST_NUM_EXPECTED_VALS);
		}

		/* Perform the actual sensor read */
		rv = sensor_read_async_mempool(&iodev_read, &sensor_read_rtio_ctx, NULL);
		zassert_ok(rv, "Could not read sensor (error %d, iteration %d/%d)", rv,
			   iteration + 1, CONFIG_GENERIC_SENSOR_TEST_NUM_EXPECTED_VALS);

		/* Wait for a CQE */
		struct rtio_cqe *cqe = rtio_cqe_consume_block(&sensor_read_rtio_ctx);
		int result = cqe->result;
		uint8_t *buf = NULL;
		uint32_t buf_len = 0;

		/* Cache the data from the CQE */
		rtio_cqe_get_mempool_buffer(&sensor_read_rtio_ctx, cqe, &buf, &buf_len);

		/* Release the CQE before asserting so a failure does not leak it */
		rtio_cqe_release(&sensor_read_rtio_ctx, cqe);

		zassert_ok(result, "CQE has failed status (error %d, iteration %d/%d)", result,
			   iteration + 1, CONFIG_GENERIC_SENSOR_TEST_NUM_EXPECTED_VALS);

		const struct sensor_decoder_api *decoder;
		union sensor_data_union decoded_data;

		zassert_ok(sensor_get_decoder(dev, &decoder));

		/* Loop through each channel */
		for (int ch = 0; ch < ARRAY_SIZE(channel_table); ch++) {
			if (!channel_table[ch].supported) {
				continue;
			}

			struct sensor_decode_context ctx =
				SENSOR_DECODE_CONTEXT_INIT(decoder, buf, ch, 0);

			rv = sensor_decode(&ctx, &decoded_data, 1);
			zassert_equal(1, rv, "Could not decode (error %d, ch %d, iteration %d/%d)",
				      rv, ch, iteration + 1,
				      CONFIG_GENERIC_SENSOR_TEST_NUM_EXPECTED_VALS);

			channel_table[ch].received = true;

			/* Retrieve the actual value */
			q31_t q;
			int8_t shift;

			q = decoded_data.q31.readings[0].value;
			shift = decoded_data.q31.shift;

			/* Align everything to be a 64-bit Q32.32 number for comparison */
			int64_t expected_shifted =
				(int64_t)channel_table[ch].expected_values[iteration]
				<< channel_table[ch].expected_value_shift;
			int64_t actual_shifted = (int64_t)q << shift;
			int64_t epsilon_shifted = (int64_t)channel_table[ch].epsilon
						  << channel_table[ch].expected_value_shift;

			zassert_within(expected_shifted, actual_shifted, epsilon_shifted,
				       "Expected %lld, got %lld (shift %d, ch %d, iteration %d/%d, "
				       "Error %lld, Epsilon %lld)",
				       expected_shifted, actual_shifted, shift, ch, iteration + 1,
				       CONFIG_GENERIC_SENSOR_TEST_NUM_EXPECTED_VALS,
				       expected_shifted - actual_shifted, epsilon_shifted);
		}

		/* Release the memory */
		rtio_release_buffer(&sensor_read_rtio_ctx, buf, buf_len);

		/* Ensure all supported channels were received */
		int missing_channel_count = 0;

		for (size_t i = 0; i < ARRAY_SIZE(channel_table); i++) {
			if (channel_table[i].supported && !channel_table[i].received) {
				missing_channel_count++;
			}
		}

		zassert_equal(0, missing_channel_count, "%d channel(s) not received",
			      missing_channel_count);
	}
}

#define DECLARE_ZTEST_PER_DEVICE(n)                                                                \
	ZTEST(generic, test_##n)                                                                   \
	{                                                                                          \
		run_generic_test(DEVICE_DT_GET(n));                                                \
	}

/* Iterate through each of the emulated buses and create a test for each device. */
DT_FOREACH_CHILD_STATUS_OKAY(DT_NODELABEL(test_i2c), DECLARE_ZTEST_PER_DEVICE)
DT_FOREACH_CHILD_STATUS_OKAY(DT_NODELABEL(test_i3c), DECLARE_ZTEST_PER_DEVICE)
DT_FOREACH_CHILD_STATUS_OKAY(DT_NODELABEL(test_spi), DECLARE_ZTEST_PER_DEVICE)

ZTEST_SUITE(generic, NULL, NULL, before, NULL, NULL);
```
